# MAIN_CTRL_MMR_MAIN_CTRL_MMR_CFG0_00100000h register map
Vendor: Texas Instruments
Registers are 32-bit, read-write, reset 0x0 unless marked. A register's access mark holds for its fields unless they carry their own. Offsets are as the file gives them; [hi:lo] are bit positions; {n}, {i} and the like mark numbered series.

## main_ctrl_mmr_CFG0 (part 3 of 3)
0x4774 MAIN_CTRL_MMRCFG0_R5SS1_CORE1_RL2_CTRL — Controls operation of the RL2 Cache Controller for Main R5 Cluster1 Core1. Note this register has no effect if Main R5 Cluster0 is operating in lockstep mode.
  [9:8] R5SS1_CORE1_RL2_CTRL_RTXIP_SEL — Selects R5SS1 Core 1 OSPI0 XIP realtime access modeWhen realtime accesses are enabled, read transactions take priority over write transactions. This prevents XIP delays when Flash RWW updates are active.Field values (others are reserved):2'b00 - No realtime accesses2'b01 - Realtime access on RL2 Flash read pending2'b10 - All read accesses are realtime Reset Source: mod_g_rst_n
0x5110 MAIN_CTRL_MMRCFG0_CLAIMREG_P1_R4_READONLY ro
  [31:0] CLAIMREG_P1_R4_READONLY — Claim bits for Partition 1 Reset Source: mod_g_rst_n
0x5120 MAIN_CTRL_MMRCFG0_CLAIMREG_P1_R8_READONLY ro
  [31:0] CLAIMREG_P1_R8_READONLY — Claim bits for Partition 1 Reset Source: mod_g_rst_n
0x5124 MAIN_CTRL_MMRCFG0_CLAIMREG_P1_R9_READONLY ro
  [31:0] CLAIMREG_P1_R9_READONLY — Claim bits for Partition 1 Reset Source: mod_g_rst_n
0x6044 MAIN_CTRL_MMRCFG0_ENET1_CTRL_PROXY reset 0x2 — Controls Ethernet Port1 operation
  [2:0] ENET1_CTRL_PORT_MODE_SEL_PROXY — Selects Ethernet switch Port1 interface Field values (others are reserved):3'b000 - GMII/MII (not supported)3'b001 - RMII3'b010 - RGMII3'b011 - SGMII3'b100 - QSGMII (not supported)3'b101 - XFI (not supported)3'b110 - QSGMII_SUB (not supported)3'b111 - Reserved Reset Source: sys_por_rst_n
0x6048 MAIN_CTRL_MMRCFG0_ENET2_CTRL_PROXY reset 0x2 — Controls Ethernet Port2 operation
  [2:0] ENET2_CTRL_PORT_MODE_SEL_PROXY — Selects Ethernet switch Port2 interface Field values (others are reserved):3'b000 - GMII/MII (not supported)3'b001 - RMII3'b010 - RGMII3'b011 - SGMII3'b100 - QSGMII (not supported)3'b101 - XFI (not supported)3'b110 - QSGMII_SUB (not supported)3'b111 - Reserved Reset Source: sys_por_rst_n
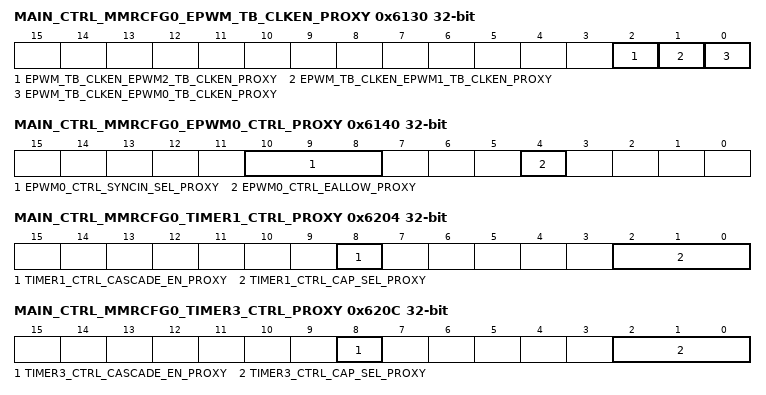
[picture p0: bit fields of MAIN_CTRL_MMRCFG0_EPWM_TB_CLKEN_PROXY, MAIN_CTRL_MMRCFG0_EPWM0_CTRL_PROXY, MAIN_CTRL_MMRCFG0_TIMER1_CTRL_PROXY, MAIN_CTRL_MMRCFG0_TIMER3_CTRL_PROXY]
0x6130 MAIN_CTRL_MMRCFG0_EPWM_TB_CLKEN_PROXY — Controls Timebase Counter of EPWM Modules
  [2] EPWM_TB_CLKEN_EPWM2_TB_CLKEN_PROXY — Enabled Timebase Clock of EPWM2 When SetField values (others are reserved):1'b0 - Disable1'b1 - Enable Reset Source: mod_g_rst_n
  [1] EPWM_TB_CLKEN_EPWM1_TB_CLKEN_PROXY — EnablesTimebase Clock of EPWM1 When SetField values (others are reserved):1'b0 - Disable1'b1 - Enable Reset Source: mod_g_rst_n
  [0] EPWM_TB_CLKEN_EPWM0_TB_CLKEN_PROXY — EnablesTimebase Clock of EPWM0 When SetField values (others are reserved):1'b0 - Disable1'b1 - Enable Reset Source: mod_g_rst_n
0x6140 MAIN_CTRL_MMRCFG0_EPWM0_CTRL_PROXY — Controls EPWM0 Operation
  [10:8] EPWM0_CTRL_SYNCIN_SEL_PROXY — Selects the source of the EPWM0 synchronization inputField values (others are reserved):3'b000 - EPWM0_SYNCIN (Pin)undefined - undefined3'b010 - TimeSync Intr Router outl.203'b011 - CPSW CPTS Compare Event Reset Source: mod_g_rst_n
  [4] EPWM0_CTRL_EALLOW_PROXY — Enable write access to EPWM tripzone registersField values (others are reserved):1'b0 - Disable1'b1 - Enable Reset Source: mod_g_rst_n
0x6144 MAIN_CTRL_MMRCFG0_EPWM1_CTRL_PROXY — Controls EPWM1 Operation
  [4] EPWM1_CTRL_EALLOW_PROXY — Enable write access to EPWM tripzone registersField values (others are reserved):1'b0 - Disable1'b1 - Enable Reset Source: mod_g_rst_n
0x6148 MAIN_CTRL_MMRCFG0_EPWM2_CTRL_PROXY — Controls EPWM2 Operation
  [4] EPWM2_CTRL_EALLOW_PROXY — Enable write access to EPWM tripzone registersField values (others are reserved):1'b0 - Disable1'b1 - Enable Reset Source: mod_g_rst_n
0x6200 MAIN_CTRL_MMRCFG0_TIMER0_CTRL_PROXY — Controls TIMER0 operation
  [2:0] TIMER0_CTRL_CAP_SEL_PROXY — Selects the TIMERIO input pin for capture input signal. This control is only used when TIMER0 is configured for capture operation.Field values (others are reserved):3'b000 - Use TIMERIO0 pin3'b001 - Use TIMERIO1 pin3'b010 - Use TIMERIO2 pin3'b011 - Use TIMERIO3 pin3'b100 - Use TIMERIO4 pin3'b101 - Use TIMERIO5 pin3'b110 - Use TIMERIO6 pin3'b111 - Use TIMERIO7 pin Reset Source: sys_por_rst_n
0x6204 MAIN_CTRL_MMRCFG0_TIMER1_CTRL_PROXY — Controls TIMER1 operation
  [8] TIMER1_CTRL_CASCADE_EN_PROXY — Enables cascading of TIMER1 to TIMER0Field values (others are reserved):1'b0 - Cascading disabled1'b1 - Cascading enabled Reset Source: sys_por_rst_n
  [2:0] TIMER1_CTRL_CAP_SEL_PROXY — Selects the TIMERIO input pin for capture input signal. This control is only used when TIMER1 is configured for capture operation.Field values (others are reserved):3'b000 - Use TIMERIO0 pin3'b001 - Use TIMERIO1 pin3'b010 - Use TIMERIO2 pin3'b011 - Use TIMERIO3 pin3'b100 - Use TIMERIO4 pin3'b101 - Use TIMERIO5 pin3'b110 - Use TIMERIO6 pin3'b111 - Use TIMERIO7 pin Reset Source: sys_por_rst_n
0x6208 MAIN_CTRL_MMRCFG0_TIMER2_CTRL_PROXY — Controls TIMER2 operation
  [2:0] TIMER2_CTRL_CAP_SEL_PROXY — Selects the TIMERIO input pin for capture input signal. This control is only used when TIMER2 is configured for capture operation.Field values (others are reserved):3'b000 - Use TIMERIO0 pin3'b001 - Use TIMERIO1 pin3'b010 - Use TIMERIO2 pin3'b011 - Use TIMERIO3 pin3'b100 - Use TIMERIO4 pin3'b101 - Use TIMERIO5 pin3'b110 - Use TIMERIO6 pin3'b111 - Use TIMERIO7 pin Reset Source: sys_por_rst_n
0x620C MAIN_CTRL_MMRCFG0_TIMER3_CTRL_PROXY — Controls TIMER3 operation
  [8] TIMER3_CTRL_CASCADE_EN_PROXY — Enables cascading of TIMER3 to TIMER2Field values (others are reserved):1'b0 - Cascading disabled1'b1 - Cascading enabled Reset Source: sys_por_rst_n
  [2:0] TIMER3_CTRL_CAP_SEL_PROXY — Selects the TIMERIO input pin for capture input signal. This control is only used when TIMER3 is configured for capture operation.Field values (others are reserved):3'b000 - Use TIMERIO0 pin3'b001 - Use TIMERIO1 pin3'b010 - Use TIMERIO2 pin3'b011 - Use TIMERIO3 pin3'b100 - Use TIMERIO4 pin3'b101 - Use TIMERIO5 pin3'b110 - Use TIMERIO6 pin3'b111 - Use TIMERIO7 pin Reset Source: sys_por_rst_n
0x6210 MAIN_CTRL_MMRCFG0_TIMER4_CTRL_PROXY — Controls TIMER4 operation
  [2:0] TIMER4_CTRL_CAP_SEL_PROXY — Selects the TIMERIO input pin for capture input signal. This control is only used when TIMER4 is configured for capture operation.Field values (others are reserved):3'b000 - Use TIMERIO0 pin3'b001 - Use TIMERIO1 pin3'b010 - Use TIMERIO2 pin3'b011 - Use TIMERIO3 pin3'b100 - Use TIMERIO4 pin3'b101 - Use TIMERIO5 pin3'b110 - Use TIMERIO6 pin3'b111 - Use TIMERIO7 pin Reset Source: sys_por_rst_n
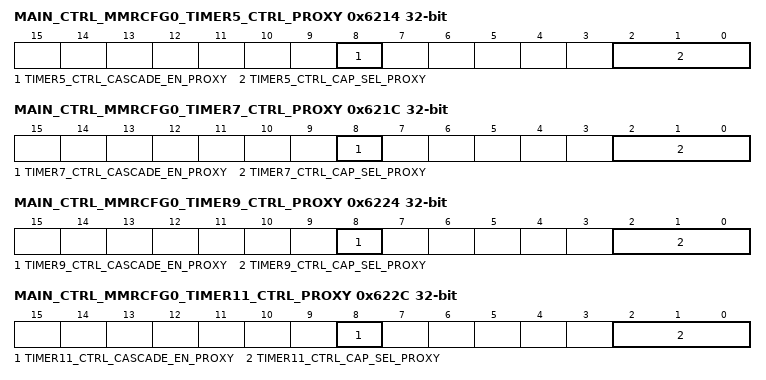
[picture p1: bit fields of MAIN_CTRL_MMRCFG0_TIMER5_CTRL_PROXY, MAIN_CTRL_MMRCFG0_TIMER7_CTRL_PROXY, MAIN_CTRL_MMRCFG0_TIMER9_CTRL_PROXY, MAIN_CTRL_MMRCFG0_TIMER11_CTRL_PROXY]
0x6214 MAIN_CTRL_MMRCFG0_TIMER5_CTRL_PROXY — Controls TIMER5 operation
  [8] TIMER5_CTRL_CASCADE_EN_PROXY — Enables cascading of TIMER5 to TIMER4Field values (others are reserved):1'b0 - Cascading disabled1'b1 - Cascading enabled Reset Source: sys_por_rst_n
  [2:0] TIMER5_CTRL_CAP_SEL_PROXY — Selects the TIMERIO input pin for capture input signal. This control is only used when TIMER5 is configured for capture operation.Field values (others are reserved):3'b000 - Use TIMERIO0 pin3'b001 - Use TIMERIO1 pin3'b010 - Use TIMERIO2 pin3'b011 - Use TIMERIO3 pin3'b100 - Use TIMERIO4 pin3'b101 - Use TIMERIO5 pin3'b110 - Use TIMERIO6 pin3'b111 - Use TIMERIO7 pin Reset Source: sys_por_rst_n
0x6218 MAIN_CTRL_MMRCFG0_TIMER6_CTRL_PROXY — Controls TIMER6 operation
  [2:0] TIMER6_CTRL_CAP_SEL_PROXY — Selects the TIMERIO input pin for capture input signal. This control is only used when TIMER6 is configured for capture operation.Field values (others are reserved):3'b000 - Use TIMERIO0 pin3'b001 - Use TIMERIO1 pin3'b010 - Use TIMERIO2 pin3'b011 - Use TIMERIO3 pin3'b100 - Use TIMERIO4 pin3'b101 - Use TIMERIO5 pin3'b110 - Use TIMERIO6 pin3'b111 - Use TIMERIO7 pin Reset Source: sys_por_rst_n
0x621C MAIN_CTRL_MMRCFG0_TIMER7_CTRL_PROXY — Controls TIMER7 operation
  [8] TIMER7_CTRL_CASCADE_EN_PROXY — Enables cascading of TIMER7 to TIMER6Field values (others are reserved):1'b0 - Cascading disabled1'b1 - Cascading enabled Reset Source: sys_por_rst_n
  [2:0] TIMER7_CTRL_CAP_SEL_PROXY — Selects the TIMERIO input pin for capture input signal. This control is only used when TIMER7 is configured for capture operation.Field values (others are reserved):3'b000 - Use TIMERIO0 pin3'b001 - Use TIMERIO1 pin3'b010 - Use TIMERIO2 pin3'b011 - Use TIMERIO3 pin3'b100 - Use TIMERIO4 pin3'b101 - Use TIMERIO5 pin3'b110 - Use TIMERIO6 pin3'b111 - Use TIMERIO7 pin Reset Source: sys_por_rst_n
0x6220 MAIN_CTRL_MMRCFG0_TIMER8_CTRL_PROXY — Controls TIMER8 operation
  [2:0] TIMER8_CTRL_CAP_SEL_PROXY — Selects the TIMERIO input pin for capture input signal. This control is only used when TIMER8 is configured for capture operation.Field values (others are reserved):3'b000 - Use TIMERIO0 pin3'b001 - Use TIMERIO1 pin3'b010 - Use TIMERIO2 pin3'b011 - Use TIMERIO3 pin3'b100 - Use TIMERIO4 pin3'b101 - Use TIMERIO5 pin3'b110 - Use TIMERIO6 pin3'b111 - Use TIMERIO7 pin Reset Source: sys_por_rst_n
0x6224 MAIN_CTRL_MMRCFG0_TIMER9_CTRL_PROXY — Controls TIMER9 operation
  [8] TIMER9_CTRL_CASCADE_EN_PROXY — Enables cascading of TIMER9 to TIMER8Field values (others are reserved):1'b0 - Cascading disabled1'b1 - Cascading enabled Reset Source: sys_por_rst_n
  [2:0] TIMER9_CTRL_CAP_SEL_PROXY — Selects the TIMERIO input pin for capture input signal. This control is only used when TIMER9 is configured for capture operation.Field values (others are reserved):3'b000 - Use TIMERIO0 pin3'b001 - Use TIMERIO1 pin3'b010 - Use TIMERIO2 pin3'b011 - Use TIMERIO3 pin3'b100 - Use TIMERIO4 pin3'b101 - Use TIMERIO5 pin3'b110 - Use TIMERIO6 pin3'b111 - Use TIMERIO7 pin Reset Source: sys_por_rst_n
0x6228 MAIN_CTRL_MMRCFG0_TIMER10_CTRL_PROXY — Controls TIMER10 operation
  [2:0] TIMER10_CTRL_CAP_SEL_PROXY — Selects the TIMERIO input pin for capture input signal. This control is only used when TIMER10 is configured for capture operation.Field values (others are reserved):3'b000 - Use TIMERIO0 pin3'b001 - Use TIMERIO1 pin3'b010 - Use TIMERIO2 pin3'b011 - Use TIMERIO3 pin3'b100 - Use TIMERIO4 pin3'b101 - Use TIMERIO5 pin3'b110 - Use TIMERIO6 pin3'b111 - Use TIMERIO7 pin Reset Source: sys_por_rst_n
0x622C MAIN_CTRL_MMRCFG0_TIMER11_CTRL_PROXY — Controls TIMER11 operation
  [8] TIMER11_CTRL_CASCADE_EN_PROXY — Enables cascading of TIMER11 to TIMER10Field values (others are reserved):1'b0 - Cascading disabled1'b1 - Cascading enabled Reset Source: sys_por_rst_n
  [2:0] TIMER11_CTRL_CAP_SEL_PROXY — Selects the TIMERIO input pin for capture input signal. This control is only used when TIMER11 is configured for capture operation.Field values (others are reserved):3'b000 - Use TIMERIO0 pin3'b001 - Use TIMERIO1 pin3'b010 - Use TIMERIO2 pin3'b011 - Use TIMERIO3 pin3'b100 - Use TIMERIO4 pin3'b101 - Use TIMERIO5 pin3'b110 - Use TIMERIO6 pin3'b111 - Use TIMERIO7 pin Reset Source: sys_por_rst_n
0x6230 MAIN_CTRL_MMRCFG0_TIMER12_CTRL_PROXY — Controls TIMER12 operation
  [2:0] TIMER12_CTRL_CAP_SEL_PROXY — Selects the TIMERIO input pin for capture input signal. This control is only used when TIMER12 is configured for capture operation.Field values (others are reserved):3'b000 - Use TIMERIO0 pin3'b001 - Use TIMERIO1 pin3'b010 - Use TIMERIO2 pin3'b011 - Use TIMERIO3 pin3'b100 - Use TIMERIO4 pin3'b101 - Use TIMERIO5 pin3'b110 - Use TIMERIO6 pin3'b111 - Use TIMERIO7 pin Reset Source: sys_por_rst_n
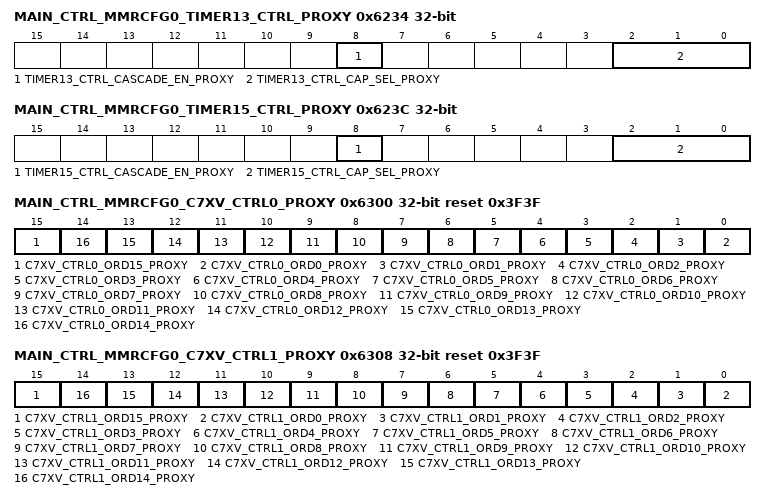
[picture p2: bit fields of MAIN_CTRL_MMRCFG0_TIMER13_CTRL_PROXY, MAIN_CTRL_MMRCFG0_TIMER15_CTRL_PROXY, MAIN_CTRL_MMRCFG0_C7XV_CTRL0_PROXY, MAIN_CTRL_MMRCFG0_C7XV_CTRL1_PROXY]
0x6234 MAIN_CTRL_MMRCFG0_TIMER13_CTRL_PROXY — Controls TIMER13 operation
  [8] TIMER13_CTRL_CASCADE_EN_PROXY — Enables cascading of TIMER13 to TIMER12Field values (others are reserved):1'b0 - Cascading disabled1'b1 - Cascading enabled Reset Source: sys_por_rst_n
  [2:0] TIMER13_CTRL_CAP_SEL_PROXY — Selects the TIMERIO input pin for capture input signal. This control is only used when TIMER13 is configured for capture operation.Field values (others are reserved):3'b000 - Use TIMERIO0 pin3'b001 - Use TIMERIO1 pin3'b010 - Use TIMERIO2 pin3'b011 - Use TIMERIO3 pin3'b100 - Use TIMERIO4 pin3'b101 - Use TIMERIO5 pin3'b110 - Use TIMERIO6 pin3'b111 - Use TIMERIO7 pin Reset Source: sys_por_rst_n
0x6238 MAIN_CTRL_MMRCFG0_TIMER14_CTRL_PROXY — Controls TIMER14 operation
  [2:0] TIMER14_CTRL_CAP_SEL_PROXY — Selects the TIMERIO input pin for capture input signal. This control is only used when TIMER14 is configured for capture operation.Field values (others are reserved):3'b000 - Use TIMERIO0 pin3'b001 - Use TIMERIO1 pin3'b010 - Use TIMERIO2 pin3'b011 - Use TIMERIO3 pin3'b100 - Use TIMERIO4 pin3'b101 - Use TIMERIO5 pin3'b110 - Use TIMERIO6 pin3'b111 - Use TIMERIO7 pin Reset Source: sys_por_rst_n
0x623C MAIN_CTRL_MMRCFG0_TIMER15_CTRL_PROXY — Controls TIMER15 operation
  [8] TIMER15_CTRL_CASCADE_EN_PROXY — Enables cascading of TIMER15 to TIMER14Field values (others are reserved):1'b0 - Cascading disabled1'b1 - Cascading enabled Reset Source: sys_por_rst_n
  [2:0] TIMER15_CTRL_CAP_SEL_PROXY — Selects the TIMERIO input pin for capture input signal. This control is only used when TIMER15 is configured for capture operation.Field values (others are reserved):3'b000 - Use TIMERIO0 pin3'b001 - Use TIMERIO1 pin3'b010 - Use TIMERIO2 pin3'b011 - Use TIMERIO3 pin3'b100 - Use TIMERIO4 pin3'b101 - Use TIMERIO5 pin3'b110 - Use TIMERIO6 pin3'b111 - Use TIMERIO7 pin Reset Source: sys_por_rst_n
{0x6280+4i} MAIN_CTRL_MMRCFG0_TIMERIO{i}_CTRL_PROXY (i=0..7) — Controls Timer IO muxing
  [3:0] TIMERIO{i}_CTRL_OUT_SEL_PROXY — Selects the source of the TIMERIO{i} outputField values (others are reserved):4'b0000 - TIMERIO{i} is driven by TIMER0 output4'b0001 - TIMERIO{i} is driven by TIMER1 output4'b0010 - TIMERIO{i} is driven by TIMER2 output4'b0011 - TIMERIO{i} is driven by TIMER3 output4'b0100 - TIMERIO{i} is driven by TIMER4 output4'b0101 - TIMERIO{i} is driven by TIMER5 output4'b0110 - TIMERIO{i} is driven by TIMER6 output4'b0111 - TIMERIO{i} is driven by TIMER7 output4'b1000 - TIMERIO{i} is driven by TIMER8 output4'b1001 - TIMERIO{i} is driven by TIMER9 output4'b1010 - TIMERIO{i} is driven by TIMER10 output4'b1011 - TIMERIO{i} is driven by TIMER11 output4'b1100 - TIMERIO{i} is driven by TIMER12 output4'b1101 - TIMERIO{i} is driven by TIMER13 output4'b1110 - TIMERIO{i} is driven by TIMER14 output4'b1111 - TIMERIO{i} is driven by TIMER15 output Reset Source: sys_por_rst_n
0x6300 MAIN_CTRL_MMRCFG0_C7XV_CTRL0_PROXY reset 0x3F3F — Controls Relaxed Ordering by OrderID for the C7xv0 L2 Memory from external accesses. Ordering of accesses to the same 4KB L2 Block is relaxed either between Reads (more strict) or Between both Reads and Writes (more relaxed)
  [15] C7XV_CTRL0_ORD15_PROXY — Ordering Rule for Order ID 15 Field values (others are reserved):1'b0 - RELAXED_READ1'b1 - RELAXED_R_TO_W Reset Source: mod_por_rst_n
  [n] C7XV_CTRL0_ORD{n}_PROXY (n=0..14) — Ordering Rule for Order ID {n}Field values (others are reserved):1'b0 - RELAXED_READ1'b1 - RELAXED_R_TO_W Reset Source: mod_por_rst_n
0x6308 MAIN_CTRL_MMRCFG0_C7XV_CTRL1_PROXY reset 0x3F3F — Controls Relaxed Ordering by OrderID for the C7xv1 L2 Memory from external accesses. Ordering of accesses to the same 4KB L2 Block is relaxed either between Reads (more strict) or Between both Reads and Writes (more relaxed)
  [15] C7XV_CTRL1_ORD15_PROXY — Ordering Rule for Order ID 15 Field values (others are reserved):1'b0 - RELAXED_READ1'b1 - RELAXED_R_TO_W Reset Source: mod_por_rst_n
  [n] C7XV_CTRL1_ORD{n}_PROXY (n=0..14) — Ordering Rule for Order ID {n}Field values (others are reserved):1'b0 - RELAXED_READ1'b1 - RELAXED_R_TO_W Reset Source: mod_por_rst_n
0x64C0 MAIN_CTRL_MMRCFG0_EMMC0_STAT_PROXY ro — For determining state of MMCSD 1.8V Signalling
  [0] EMMC0_STAT_SIG1P8_EN_PROXY — Status of 1.8V Signal Activate from EMMC0 ModuleField values (others are reserved):1'b0 - DISABLE_1P8V_SIGNALLING1'b1 - ENABLE_1P8V_SIGNALLING Reset Source: mod_g_rst_n
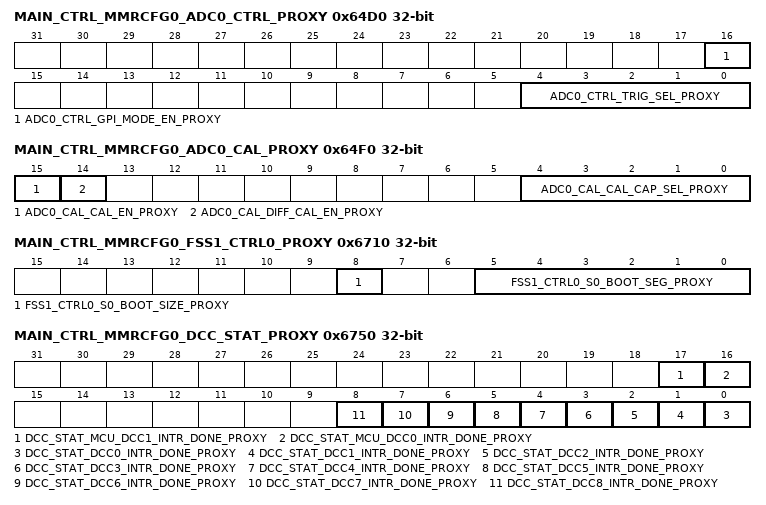
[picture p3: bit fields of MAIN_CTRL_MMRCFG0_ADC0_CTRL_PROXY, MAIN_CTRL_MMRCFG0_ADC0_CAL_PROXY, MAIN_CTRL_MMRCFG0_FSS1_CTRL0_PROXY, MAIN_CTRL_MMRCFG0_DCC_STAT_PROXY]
0x64D0 MAIN_CTRL_MMRCFG0_ADC0_CTRL_PROXY — Controls operation of ADC0
  [16] ADC0_CTRL_GPI_MODE_EN_PROXY — Enables ADC0 data pins to be used as general purpose inputs when set. This signal is tied to the en_dig_test input of MCU_ADC0 Reset Source: mod_g_rst_n
  [4:0] ADC0_CTRL_TRIG_SEL_PROXY — Selects the source of the ADC hardware event triggerField values (others are reserved):5'b00000 - ADC_EXT_TRIGGER0 (Pin)5'b00001 - 0 - Reserved5'b00010 - EPWM SOCA_OUT5'b00011 - EPWM SOCB_OUT5'b00100 - 0 - Reserved5'b00101 - 0 - Reserved5'b00110 - 0 - Reserved5'b00111 - 0 - Reserved5'b01000 - 0 - Reserved5'b01001 - 0 - Reserved5'b01010 - 0 - Reserved5'b01011 - 0 - Reserved5'b01100 - 0 - Reserved5'b01101 - 0 - Reserved5'b01110 - WKUP_TIMER0 PWM5'b01111 - WKUP_TIMER1 PWM5'b10000 - TIMER0 PWM 5'b10001 - TIMER1 PWM 5'b10010 - TIMER2 PWM 5'b10011 - TIMER3 PWM 5'b10100 - TIMER4 PWM 5'b10101 - TIMER5 PWM 5'b10110 - TIMER6 PWM 5'b10111 - TIMER7 PWM 5'b11000 - TIMER8 PWM 5'b11001 - TIMER9 PWM 5'b11010 - TIMER10 PWM 5'b11011 - TIMER11 PWM 5'b11100 - TIMER12 PWM5'b11101 - TIMER13_PWM5'b11110 - TIMER14_pWM5'b11111 - Timer15_PWM Reset Source: mod_g_rst_n
0x64F0 MAIN_CTRL_MMRCFG0_ADC0_CAL_PROXY — Controls ADC0 calibration sequence (not used)
  [15] ADC0_CAL_CAL_EN_PROXY — Enable single-ended calibrationSet to 1 to begin single-ended calibration Reset Source: mod_g_rst_n
  [14] ADC0_CAL_DIFF_CAL_EN_PROXY — Enable differential calibrationSet to 1 to begin differential calibration Reset Source: mod_g_rst_n
  [4:0] ADC0_CAL_CAL_CAP_SEL_PROXY — Select capacitor for calibrationBits correspond to C5:C1 Reset Source: mod_g_rst_n
0x6700 MAIN_CTRL_MMRCFG0_FSS0_CTRL0_PROXY — Controls Flash boot region size for Flash Subsystem0
  [19:0] FSS0_CTRL0_S0_BOOT_SEG_PROXY — Selects the flash boot segment sizeField values (others are reserved):20'h00001 - 4 kB20'h00002 - 8 kB20'h00004 - 16 kB20'h00008 - 32 kB20'h00010 - 64 kB20'h00020 - 128 kB20'h00040 - 256 kB20'h00080 - 512 kB20'h00100 - 1 MB20'h00200 - 2 MB20'h00400 - 4 MB20'h00800 - 8 MB20'h01000 - 16 MB20'h02000 - 32 MB20'h04000 - 64 MB20'h08000 - 128 MB20'h10000 - 256 MB20'h20000 - 512 MB20'h40000 - 1 GB20'h80000 - 2 GB Reset Source: mod_g_rst_n
0x6704 MAIN_CTRL_MMRCFG0_FSS0_CTRL1_PROXY — Controls Flash boot region placement for Flash Subsystem0
  [19:0] FSS0_CTRL1_S0_BOOT_MASK_PROXY — Determines which (upper 20) address bits to replace with boot_seg signals when accessing the Boot Region (Region 1) Reset Source: mod_g_rst_n
0x6710 MAIN_CTRL_MMRCFG0_FSS1_CTRL0_PROXY — Controls Flash boot region size and placement for Flash Subsystem1
  [8] FSS1_CTRL0_S0_BOOT_SIZE_PROXY — Selects the size of the boot block to be used for the S0 (OSPI1) flash interface Reset Source: mod_g_rst_n
  [5:0] FSS1_CTRL0_S0_BOOT_SEG_PROXY — Selects the boot block to be used for the S0 (OSPI1) flash interface. If the s0_boot_size is 128 MB then only bits [4:0] of this field are used. Care must be taken to account for the address translation as to not fall off or wrap the address of the flash. (e.g. if both ECC and authentication are enabled for 64 MB boot, the highest valid block number is is 49, as sector 50 is only .2M Bytes in size.) Reset Source: mod_g_rst_n
0x6750 MAIN_CTRL_MMRCFG0_DCC_STAT_PROXY ro — Interrupt Status of Individual DCC Modules
  [17] DCC_STAT_MCU_DCC1_INTR_DONE_PROXY — MCU_DCC1 Done Interrupt StatusField values (others are reserved):1'b0 - CLR1'b1 - PEND Reset Source: mod_g_rst_n
  [16] DCC_STAT_MCU_DCC0_INTR_DONE_PROXY — MCU_DCC0 Done Interrupt StatusField values (others are reserved):1'b0 - CLR1'b1 - PEND Reset Source: mod_g_rst_n
  [n] DCC_STAT_DCC{n}_INTR_DONE_PROXY (n=0..8) — DCC{n} Done Interrupt StatusField values (others are reserved):1'b0 - CLR1'b1 - PEND Reset Source: mod_g_rst_n
0x6760 MAIN_CTRL_MMRCFG0_R5SS0_CORE0_RL2_CTRL_PROXY — Controls operation of the RL2 Cache Controller for Main R5 Cluster0 Core0
  [9:8] R5SS0_CORE0_RL2_CTRL_RTXIP_SEL_PROXY — Selects R5SS0 Core 0 OSPI0 XIP realtime access modeWhen realtime accesses are enabled, read transactions take priority over write transactions. This prevents XIP delays when Flash RWW updates are active.Field values (others are reserved):2'b00 - No realtime accesses2'b01 - Realtime access on RL2 Flash read pending2'b10 - All read accesses are realtime Reset Source: mod_g_rst_n
0x6764 MAIN_CTRL_MMRCFG0_R5SS0_CORE1_RL2_CTRL_PROXY — Controls operation of the RL2 Cache Controller for Main R5 Cluster0 Core1. Note this register has no effect if Main R5 Cluster0 is operating in lockstep mode.
  [9:8] R5SS0_CORE1_RL2_CTRL_RTXIP_SEL_PROXY — Selects R5SS0 Core 1 OSPI0 XIP realtime access modeWhen realtime accesses are enabled, read transactions take priority over write transactions. This prevents XIP delays when Flash RWW updates are active.Field values (others are reserved):2'b00 - No realtime accesses2'b01 - Realtime access on RL2 Flash read pending2'b10 - All read accesses are realtime Reset Source: mod_g_rst_n
0x6770 MAIN_CTRL_MMRCFG0_R5SS1_CORE0_RL2_CTRL_PROXY — Controls operation of the RL2 Cache Controller for Main R5 Cluster1 Core0
  [9:8] R5SS1_CORE0_RL2_CTRL_RTXIP_SEL_PROXY — Selects R5SS1 Core 0 OSPI0 XIP realtime access modeWhen realtime accesses are enabled, read transactions take priority over write transactions. This prevents XIP delays when Flash RWW updates are active.Field values (others are reserved):2'b00 - No realtime accesses2'b01 - Realtime access on RL2 Flash read pending2'b10 - All read accesses are realtime Reset Source: mod_g_rst_n
0x6774 MAIN_CTRL_MMRCFG0_R5SS1_CORE1_RL2_CTRL_PROXY — Controls operation of the RL2 Cache Controller for Main R5 Cluster1 Core1. Note this register has no effect if Main R5 Cluster0 is operating in lockstep mode.
  [9:8] R5SS1_CORE1_RL2_CTRL_RTXIP_SEL_PROXY — Selects R5SS1 Core 1 OSPI0 XIP realtime access modeWhen realtime accesses are enabled, read transactions take priority over write transactions. This prevents XIP delays when Flash RWW updates are active.Field values (others are reserved):2'b00 - No realtime accesses2'b01 - Realtime access on RL2 Flash read pending2'b10 - All read accesses are realtime Reset Source: mod_g_rst_n
{0x7100+4i} MAIN_CTRL_MMRCFG0_CLAIMREG_P1_R{i} (i=0..14)
  [31:0] CLAIMREG_P1_R{i} — Claim bits for Partition 1 Reset Source: mod_g_rst_n
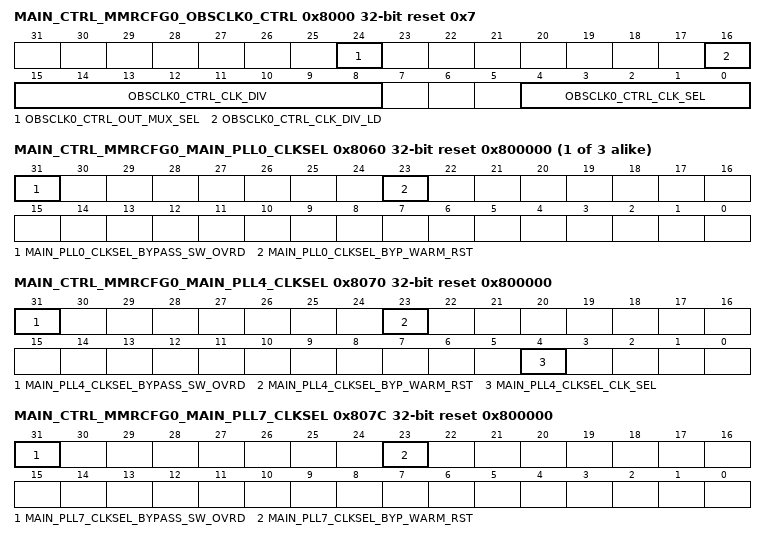
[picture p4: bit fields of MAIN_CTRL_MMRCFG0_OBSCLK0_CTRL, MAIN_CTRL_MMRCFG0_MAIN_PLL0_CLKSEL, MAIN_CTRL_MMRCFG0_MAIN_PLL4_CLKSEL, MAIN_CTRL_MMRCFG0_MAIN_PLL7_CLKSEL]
0x8000 MAIN_CTRL_MMRCFG0_OBSCLK0_CTRL reset 0x7 — This register controls which internal clock is made observable on the OBSCLK0/1 output pins
  [24] OBSCLK0_CTRL_OUT_MUX_SEL — OBSCLK pin output mux selection. PLL4_REFCLK is the direct output from either HFOSC0 or HFOSC1.Field values (others are reserved):1'b0 - Selects the output of the CLK_DIV_OUT clock mux1'b1 - Select PLL4_REFCLK (clk_sel value must be 5'b11111) Reset Source: mod_por_rst_n
  [16] OBSCLK0_CTRL_CLK_DIV_LD — Load divisor value from clk_div field, when the bit is toggled from 0 to 1. Field values (others are reserved):1'b0 - READY1'b1 - LOAD Reset Source: mod_por_rst_n
  [15:8] OBSCLK0_CTRL_CLK_DIV — OBSCLK0 output divider. Sets divider to divide by clkdiv + 1. Divide by 1 to 256 are supported. After Writing to this field, the clk_div_ld field must be toggled. Reset Source: mod_por_rst_n
  [4:0] OBSCLK0_CTRL_CLK_SEL — OBSCLK0 clock source selection.Selects the source of the clock to be divided by the OBSCLK0 divider.Field values (others are reserved):5'b00000 - MAIN_PLL0_HSDIV0_CLKOUT5'b00001 - MAIN_PLL1_HSDIV0_CLKOUT5'b00010 - MAIN_PLL2_HSDIV0_CLKOUT5'b00011 - MAIN_PLL4_HSDIV0_CLKOUT5'b00100 - MAIN_PLL14_HSDIV0_CLKOUT5'b00101 - CLK_12M_RC5'b00110 - HFOSC0_CLKOUT_32K5'b00111 - PLLCTRL_OBSCLK5'b01000 - HFOSC0_CLKOUT5'b01001 - CLK_32K_RC5'b01010 - CPSW0_CPTS_GENF05'b01011 - CPSW0_CPTS_GENF15'b01100 - MCU_PLL0_HSDIV0_CLKOUT5'b01101 - MAIN_PLL15_HSDIV0_CLKOUTundefined - undefinedundefined - undefinedundefined - undefined5'b10000 - MAIN_SYSCLK05'b10001 - DEVICE_CLKOUT_32Kundefined - undefined5'b10011 - C7XV_CLK_DIV4undefined - undefinedundefined - undefined5'b11111 - OFF (Must Select this option when out_mux_sel is set to PLL4_REFCLK) Reset Source: mod_por_rst_n
0x8010 MAIN_CTRL_MMRCFG0_CLKOUT_CTRL — Enables and selects clock source of CPSW CLKOUT pin
  [0] CLKOUT_CTRL_CLK_SEL — Selects CLKOUT clock sourceField values (others are reserved):1'b0 - MAIN_PLL2_HSDIV1_CLKOUT / 51'b1 - MAIN_PLL2_HSDIV1_CLKOUT / 10 Reset Source: mod_g_rst_n
{0x8060+4i} MAIN_CTRL_MMRCFG0_MAIN_PLL{i}_CLKSEL reset 0x800000 (i=0..2) — Controls the clock source for MAIN voltage domain PLL{i}
  [31] MAIN_PLL{i}_CLKSEL_BYPASS_SW_OVRD — PLL Bypass warm reset software overrideWhen set, enables software control of exit from bypass mode on a main_reset_z for MAIN PLL{i}. This bit must not be set until after the corresponding byp_warm_rst bit has been cleared or the PLL will immediately enter bypass mode.Field values (others are reserved):1'b0 - Disable1'b1 - Enable Reset Source: sys_por_rst_n
  [23] MAIN_PLL{i}_CLKSEL_BYP_WARM_RST — PLL bypass mode after warm reset.This bit is only valid when bypass_sw_ovrd is set to 1'b1 to enable bypass software override.This bit is set (1'b1) when a MAIN warm reset occurs and will keep MAIN PLL{i} in bypass mode after reset exit until cleared by software.Field values (others are reserved):1'b0 - EXIT_BYPASS1'b1 - MAINTAIN_BYPASS Reset Source: main_chip1_rst_n
0x8070 MAIN_CTRL_MMRCFG0_MAIN_PLL4_CLKSEL reset 0x800000 — Controls the clock source for MAIN voltage domain PLL4
  [31] MAIN_PLL4_CLKSEL_BYPASS_SW_OVRD — PLL Bypass warm reset software overrideWhen set, enables software control of exit from bypass mode on a main_reset_z for MAIN PLL4. This bit must not be set until after the corresponding byp_warm_rst bit has been cleared or the PLL will immediately enter bypass mode.Field values (others are reserved):1'b0 - Disable1'b1 - Enable Reset Source: sys_por_rst_n
  [23] MAIN_PLL4_CLKSEL_BYP_WARM_RST — PLL bypass mode after warm reset.This bit is only valid when bypass_sw_ovrd is set to 1'b1 to enable bypass software override.This bit is set (1'b1) when a MAIN warm reset occurs and will keep MAIN PLL4 in bypass mode after reset exit until cleared by software.Field values (others are reserved):1'b0 - EXIT_BYPASS1'b1 - MAINTAIN_BYPASS Reset Source: main_chip1_rst_n
  [4] MAIN_PLL4_CLKSEL_CLK_SEL — Selects the clock source for MAIN PLL4 1'b0 - Use HFOSC0_CLKOUT 1'b1 - Use HFOSC1_CLKOUT Reset Source: mod_g_rst_n
0x807C MAIN_CTRL_MMRCFG0_MAIN_PLL7_CLKSEL reset 0x800000 — Controls the clock source for MAIN voltage domain PLL7
  [31] MAIN_PLL7_CLKSEL_BYPASS_SW_OVRD — PLL Bypass warm reset software overrideWhen set, enables software control of exit from bypass mode on a main_reset_z for MAIN PLL7. This bit must not be set until after the corresponding byp_warm_rst bit has been cleared or the PLL will immediately enter bypass mode.Field values (others are reserved):1'b0 - Disable1'b1 - Enable Reset Source: sys_por_rst_n
  [23] MAIN_PLL7_CLKSEL_BYP_WARM_RST — PLL bypass mode after warm reset.This bit is only valid when bypass_sw_ovrd is set to 1'b1 to enable bypass software override.This bit is set (1'b1) when a MAIN warm reset occurs and will keep MAIN PLL7 in bypass mode after reset exit until cleared by software.Field values (others are reserved):1'b0 - EXIT_BYPASS1'b1 - MAINTAIN_BYPASS Reset Source: main_chip1_rst_n
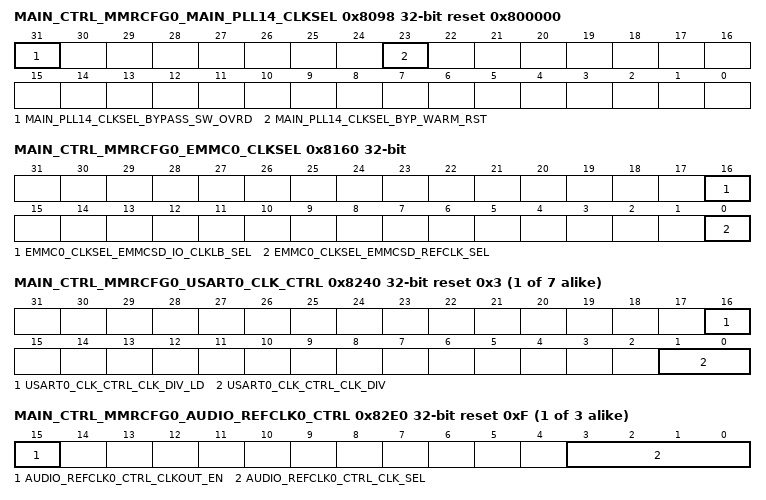
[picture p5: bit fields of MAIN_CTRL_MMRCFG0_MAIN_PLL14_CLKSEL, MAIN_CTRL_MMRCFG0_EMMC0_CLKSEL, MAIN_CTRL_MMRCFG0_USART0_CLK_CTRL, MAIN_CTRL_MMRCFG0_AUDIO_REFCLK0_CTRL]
0x8098 MAIN_CTRL_MMRCFG0_MAIN_PLL14_CLKSEL reset 0x800000 — Controls the clock source for MAIN voltage domain PLL14
  [31] MAIN_PLL14_CLKSEL_BYPASS_SW_OVRD — PLL Bypass warm reset software overrideWhen set, enables software control of exit from bypass mode on a main_reset_z for MAIN PLL14. This bit must not be set until after the corresponding byp_warm_rst bit has been cleared or the PLL will immediately enter bypass mode.Field values (others are reserved):1'b0 - Disable1'b1 - Enable Reset Source: sys_por_rst_n
  [23] MAIN_PLL14_CLKSEL_BYP_WARM_RST — PLL bypass mode after warm reset.This bit is only valid when bypass_sw_ovrd is set to 1'b1 to enable bypass software override.This bit is set (1'b1) when a MAIN warm reset occurs and will keep MAIN PLL14 in bypass mode after reset exit until cleared by software.Field values (others are reserved):1'b0 - EXIT_BYPASS1'b1 - MAINTAIN_BYPASS Reset Source: main_chip1_rst_n
0x8140 MAIN_CTRL_MMRCFG0_CPSW_CLKSEL reset 0x7 — Selects the CP Switch clock sources
  [2:0] CPSW_CLKSEL_CPTS_CLKSEL — Selects the clock source for the CPSW Ethernet switch Common Platform Time Stamp moduleField values (others are reserved):3'b000 - MAIN_PLL2_HSDIV5_CLKOUT3'b001 - MAIN_PLL0_HSDIV6_CLKOUT3'b010 - CP_GEMAC_CPTS0_RFT_CLK (Pin)3'b011 - Reserved3'b100 - MCU_EXT_REFCLK0 (Pin)3'b101 - EXT_REFCLK1 (Pin)3'b110 - SERDES0_IP1_LN0_TXMCLKundefined - undefined3'b111 - MAIN_SYSCLK0 Reset Source: mod_por_rst_n
0x8160 MAIN_CTRL_MMRCFG0_EMMC0_CLKSEL — Selects the functional clock source for 8-bit eMMC0
  [16] EMMC0_CLKSEL_EMMCSD_IO_CLKLB_SEL — Selects IO Pad Loopback for the MMC ModuleField values (others are reserved):1'b0 - Loopback from Unbonded Pad MMCSD0_CLKLB1'b1 - Loopback from IO Pin MMCSD0_CLK Reset Source: mod_g_rst_n
  [0] EMMC0_CLKSEL_EMMCSD_REFCLK_SEL — Selects the functional clock for the MMC ModuleField values (others are reserved):1'b0 - MAIN_PLL0_HSDIV5_CLKOUT1'b1 - MAIN_PLL2_HSDIV2_CLKOUT Reset Source: mod_g_rst_n
{0x81B0+4i} MAIN_CTRL_MMRCFG0_TIMER{i}_CLKSEL (i=0..15) — Timer{i} functional clock selection control
  [3:0] TIMER{i}_CLKSEL_CLK_SEL — Timer functional clock input select control.Field values (others are reserved):4'b0000 - HFOSC0_CLKOUT4'b0001 - DEVICE_CLKOUT_32K4'b0010 - MAIN_PLL0_HSDIV7_CLKOUT4'b0011 - CLK_12M_RC4'b0100 - MCU_EXT_REFCLK0 (Pin)4'b0101 - EXT_REFCLK1 (Pin)4'b0110 - Reserved4'b0111 - CP_GEMAC_CPTS0_RFT_CLK (Pin)4'b1000 - MAIN_PLL1_HSDIV3_CLKOUT4'b1001 - MAIN_PLL2_HSDIV6_CLKOUT4'b1010 - CPSW0_CPTS_GENF04'b1011 - CPSW0_CPTS_GENF14'b1100 - Reserved Reset Source: sys_por_rst_n
{0x8200+4i} MAIN_CTRL_MMRCFG0_SPI{i}_CLKSEL (i=0..4) — SPI{i} clock control
  [16] SPI{i}_CLKSEL_MSTR_LB_CLKSEL — Controller mode receive capture clock loopback selectionField values (others are reserved):1'b0 - INTERNAL_LOOPBACK1'b1 - EXTERNAL_LOOPBACK Reset Source: mod_g_rst_n
{0x8240+4i} MAIN_CTRL_MMRCFG0_USART{i}_CLK_CTRL reset 0x3 (i=0..6) — Selects the clock divider of the USART{i} functional clock
  [16] USART{i}_CLK_CTRL_CLK_DIV_LD — Load the output divider valueWriting 1 to this bit will generate a load pulse to load the USART{i} clock programmable divider value. This bit can be cleared but must not be set in the same write cycle in which the clk_div value is changed. Field values (others are reserved):1'b0 - READY1'b1 - LOAD Reset Source: mod_g_rst_n
  [1:0] USART{i}_CLK_CTRL_CLK_DIV — Selects the clock divider value. Supports divide values of 1 to 4 Default is /4. To load the new divider value the clk_div_ld bit must be cleared and then set to 1.Field values (others are reserved):2'b00 - Divide by 12'b01 - Divide by 22'b10 - Divide by 32'b11 - Divide by 4 Reset Source: mod_g_rst_n
{0x8280+4i} MAIN_CTRL_MMRCFG0_USART{i}_CLKSEL (i=0..6) — Selects the clock source for USART{i} functional clock
  [0] USART{i}_CLKSEL_CLK_SEL — Selects the clock source for UART{i}:Field values (others are reserved):1'b0 - MAIN_PLL1_HSDIV0_CLKOUT Divider Output (See USART{i}_CLK_CTRL)1'b1 - MAIN_PLL1_HSDIV1_CLKOUT Reset Source: mod_g_rst_n
0x82B0 MAIN_CTRL_MMRCFG0_ATL_CLKSEL — Selects the source of ATL PCLK which drives ATL Measurement and Adjustment Logic
  [2:0] ATL_CLKSEL_PCLK_SEL — Selects the PCLK clock sourceField values (others are reserved):3'b000 - MAIN_PLL2_HSDIV8_CLKOUT3'b001 - MAIN_PLL1_HSDIV6_CLKOUT3'b010 - MAIN_PLL2_HSDIV0_CLKOUT3'b011 - MAIN_PLL4_HSDIV1_CLKOUT3'b100 - MAIN_PLL0_HSDIV7_CLKOUT3'b101 - MCU_EXT_REFCLK0 (Pin)3'b110 - EXT_REFCLK1 (Pin) Reset Source: mod_g_rst_n
{0x82C0+4i} MAIN_CTRL_MMRCFG0_ATL_BWS{i}_SEL (i=0..3) — Selects the word clock for the ATL channel{i} Baseband Stream
  [3:0] ATL_BWS{i}_SEL_WD_SEL — BWS source signalField values (others are reserved):4'b0000 - MCASP0_AFSR_IN4'b0001 - MCASP1_AFSR_IN4'b0010 - MCASP2_AFSR_IN4'b0011 - MCASP3_AFSR_IN4'b0100 - MCASP4_AFSR_IN4'b0101 - MCASP0_AFSX_IN4'b0110 - MCASP1_AFSX_IN4'b0111 - MCASP2_AFSX_IN4'b1000 - MCASP3_AFSX_IN4'b1001 - MCASP4_AFSX_IN4'b1010 - AUDIO_EXT_REFCLK0_IN4'b1011 - AUDIO_EXT_REFCLK1_IN4'b1100 - AUDIO_EXT_REFCLK2_IN Reset Source: mod_g_rst_n
{0x82D0+4i} MAIN_CTRL_MMRCFG0_ATL_AWS{i}_SEL (i=0..3) — Selects the word clock for the ATL channel{i} Audio Stream
  [3:0] ATL_AWS{i}_SEL_WD_SEL — AWS source signalField values (others are reserved):4'b0000 - MCASP0_AFSX_IN4'b0001 - MCASP1_AFSX_IN4'b0010 - MCASP2_AFSX_IN4'b0011 - MCASP3_AFSX_IN4'b0100 - MCASP4_AFSX_IN4'b0101 - MCASP0_AFSX_IN4'b0110 - MCASP1_AFSX_IN4'b0111 - MCASP2_AFSX_IN4'b1000 - MCASP3_AFSX_IN4'b1001 - MCASP4_AFSX_IN4'b1010 - AUDIO_EXT_REFCLK0_IN4'b1011 - AUDIO_EXT_REFCLK1_IN4'b1100 - AUDIO_EXT_REFCLK2_IN Reset Source: mod_g_rst_n
{0x82E0+4i} MAIN_CTRL_MMRCFG0_AUDIO_REFCLK{i}_CTRL reset 0xF (i=0..2) — Selects the clock source for the AUDIO_EXT_REFCLK0 output, and direction.
  [15] AUDIO_REFCLK{i}_CTRL_CLKOUT_EN — AUDIO_REFCLK {i} output enableField values (others are reserved):1'b0 - INPUT1'b1 - OUTPUT Reset Source: mod_g_rst_n
  [3:0] AUDIO_REFCLK{i}_CTRL_CLK_SEL — Selects the source of AUDIO_REFCLK{i}Field values (others are reserved):4'b0000 - MCASP0_AHCLKR4'b0001 - MCASP1_AHCLKR4'b0010 - MCASP2_AHCLKR4'b0011 - MCASP3_AHCLKR4'b0100 - MCASP4_AHCLKR4'b0101 - MCASP0_AHCLKX4'b0110 - MCASP1_AHCLKX4'b0111 - MCASP2_AHCLKX4'b1000 - MCASP3_AHCLKX4'b1001 - MCASP4_AHCLKX4'b1010 - ATCLK04'b1011 - ATCLK14'b1100 - ATCLK24'b1101 - ATCLK34'b1110 - MAIN_PLL1_HSDIV6_CLKOUTundefined - undefined4'b1111 - MAIN_PLL4_HSDIV0_CLKOUT Reset Source: mod_g_rst_n
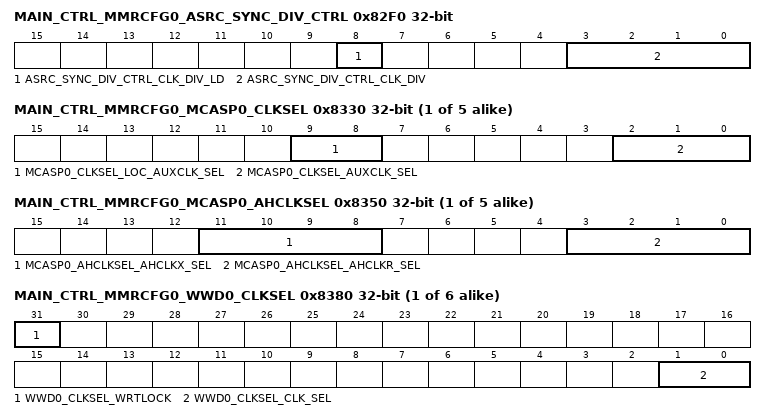
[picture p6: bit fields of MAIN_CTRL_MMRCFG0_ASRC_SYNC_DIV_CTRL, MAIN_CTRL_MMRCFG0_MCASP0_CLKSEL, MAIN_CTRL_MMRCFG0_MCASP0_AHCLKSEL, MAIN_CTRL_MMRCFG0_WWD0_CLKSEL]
0x82F0 MAIN_CTRL_MMRCFG0_ASRC_SYNC_DIV_CTRL — Selects additional divide value for the MAIN_PLL4 clock source to the ASRC RXSYNC and TXSYNC selection muxes
  [8] ASRC_SYNC_DIV_CTRL_CLK_DIV_LD — Load the divider valueWriting 1 to this bit will generate a load pulse to load the clk_div divider value. This bit can be cleared but must not be set in the same write cycle in which the clk_div value is changed. Field values (others are reserved):1'b0 - READY1'b1 - LOAD Reset Source: mod_g_rst_n
  [3:0] ASRC_SYNC_DIV_CTRL_CLK_DIV — ASRC Sync divider valueDivides MAIN_PLL4_HSDIV_CLKOUT3 by clkdiv+1. Supports divide by 1 to 16 (default to 1). To load the new divider value the clk_div_ld bit must be cleared and then set to 1. Reset Source: mod_g_rst_n
{0x8330+4i} MAIN_CTRL_MMRCFG0_MCASP{i}_CLKSEL (i=0..4) — Selects the functional clock source for McASP{i}
  [9:8] MCASP{i}_CLKSEL_LOC_AUXCLK_SEL — Selects the local clock source to use for McASP{i} AUXCLKField values (others are reserved):2'b00 - PLL4_REF_CLK (as selected by MAIN_PLL4_CLKSEL_clk_sel)2'b01 - PLL4_REF_CLK / 2 (as selected by MAIN_PLL4_CLKSEL_clk_sel)2'b10 - MAIN_PLL4_HSDIV0_CLKOUT Reset Source: mod_g_rst_n
  [2:0] MCASP{i}_CLKSEL_AUXCLK_SEL — Selects the system AUXCLK input source for McASP{i}Field values (others are reserved):3'b000 - MAIN_PLL2_HSDIV8_CLKOUT3'b001 - MAIN_PLL1_HSDIV6_CLKOUT3'b011 - AUDIO_EXT_REFCLK0 (Pin)3'b100 - AUDIO_EXT_REFCLK1 (Pin)3'b101 - AUDIO_EXT_REFCLK2 (Pin)3'b110 - ATCLK03'b111 - ATCLK1 Reset Source: mod_g_rst_n
{0x8350+4i} MAIN_CTRL_MMRCFG0_MCASP{i}_AHCLKSEL (i=0..4) — Selects the AHCLKX and AHCLKR clock source for McASP{i}
  [11:8] MCASP{i}_AHCLKSEL_AHCLKX_SEL — Selects the AHCLKX input source for McASP{i}Field values (others are reserved):4'b0000 - EXT_REFCLK1 (Pin)4'b0001 - HFOSC0_CLKOUT4'b0010 - AUDIO_EXT_REFCLK0 (Pin)4'b0011 - AUDIO_EXT_REFCLK1 (Pin)4'b0100 - AUDIO_EXT_REFCLK2 (Pin)undefined - undefined4'b0110 - MLB_IO_CLKundefined - undefined4'b1000 - ATCLK04'b1001 - ATCLK14'b1010 - ATCLK24'b1011 - ATCLK34'b1100 - CPSW CPTS GENF04'b1101 - CPSW CPTS GENF0 Reset Source: mod_g_rst_n
  [3:0] MCASP{i}_AHCLKSEL_AHCLKR_SEL — Selects the AHCLKR input source for McASP{i}Field values (others are reserved):4'b0000 - EXT_REFCLK1 (Pin)4'b0001 - HFOSC0_CLKOUT4'b0010 - AUDIO_EXT_REFCLK0 (Pin)4'b0011 - AUDIO_EXT_REFCLK1 (Pin)4'b0100 - AUDIO_EXT_REFCLK2 (Pin)undefined - undefined4'b0110 - MLB_IO_CLKundefined - undefined4'b1000 - ATCLK04'b1001 - ATCLK14'b1010 - ATCLK24'b1011 - ATCLK34'b1100 - CPSW CPTS GENF04'b1101 - CPSW CPTS GENF0 Reset Source: mod_g_rst_n
{0x8380+4i} MAIN_CTRL_MMRCFG0_WWD{i}_CLKSEL (i=0..5) — Windowed Watchdog WWD{i} functional clock selection control
  [31] WWD{i}_CLKSEL_WRTLOCK — When set, locks WWD{i}_CLKSEL from further writes until the next module reset.Field values (others are reserved):1'b0 - UNLOCKED1'b1 - LOCKED Reset Source: mod_g_rst_n
  [1:0] WWD{i}_CLKSEL_CLK_SEL — Windowed watchdog timer functional clock input select mux controlField values (others are reserved):2'b00 - HFOSC0_CLKOUT2'b01 - DEVICE_CLKOUT_32K2'b10 - CLK_12M_RC2'b11 - CLK_32K Reset Source: mod_g_rst_n
{0x83E0+4i} MAIN_CTRL_MMRCFG0_MCASP{i}_GF_CLK_SEL (i=0..4) — Performs glitchfree selection of the McASP{i} functional clock
  [16] MCASP{i}_GF_CLK_SEL_AUXCLK_GF_SEL — Provides glitch-free switching between the local and system AUXCLK source for McASP{i} based on MCASP{i}_CLKSEL loc_auxclk_sel and auxclk_sel settings.Field values (others are reserved):1'b0 - Use local AUXCLK source (as selected by loc_auxclk_sel bitfield)1'b1 - Use system AUXCLK source (as selected by auxsel_sel bitfield) Reset Source: mod_g_rst_n
{0x8480+4i} MAIN_CTRL_MMRCFG0_MCAN{i}_CLKSEL (i=0..4) — Controls the functional clock source for MCAN{i}
  [1:0] MCAN{i}_CLKSEL_CLK_SEL — MCAN functional clock selectionField values (others are reserved):2'b00 - MAIN_PLL0_HSDIV4_CLKOUT2'b01 - MCU_EXT_REFCLK0 (Pin)2'b10 - EXT_REFCLK1 (Pin)2'b11 - HFOSC0_CLKOUT Reset Source: sys_por_rst_n
{0x84C0+4i} MAIN_CTRL_MMRCFG0_ASRC0_RXSYNC{i}_SEL (i=0..3) — Selects the source signal for the ASRC0 RXSYNC{i} frame sync input
  [4:0] ASRC0_RXSYNC{i}_SEL_SYNC_SEL — RXSYNC source signalField values (others are reserved):5'b00000 - McASP0 AFSR Pin Input5'b00001 - McASP1 AFSR Pin Input5'b00010 - McASP2 AFSR Pin Input5'b00011 - McASP3 AFSR Pin Input5'b00100 - McASP4 AFSR Pin Input5'b00101 - '0' - Reserved5'b00110 - '0' - Reserved5'b00111 - '0' - Reserved5'b01000 - McASP0 AFSX Pin Input5'b01001 - McASP1 AFSX Pin Input5'b01010 - McASP2 AFSX Pin Input5'b01011 - McASP3 AFSX Pin Input5'b01100 - McASP4 AFSX Pin Input5'b01101 - '0' - Reserved5'b01110 - '0' - Reserved5'b01111 - '0' - Reserved5'b10000 - AUDIO_EXT_REFCLK0 Pin input5'b10001 - AUDIO_EXT_REFCLK1 Pin input5'b10010 - AUDIO_EXT_REFCLK2 Pin input5'b10011 - '0' - Reserved5'b10100 - ADC0_CLK5'b10101 - MLB_IO_CLK5'b10110 - MAIN_PLL4_HSDIV3_CLKOUT5'b10111 - '0' - Reserved5'b11000 - MCU_EXT_REFCLK0 Pin5'b11001 - EXT_REFCLK1 Pin5'b11010 - CPSW_CPTS_GENF05'b11011 - CPSW_CPTS_GENF15'b11100 - '0' - Reserved5'b11101 - '0' - Reserved5'b11110 - '0' - Reserved5'b11111 - '0' - Reserved Reset Source: mod_g_rst_n
{0x84D0+4i} MAIN_CTRL_MMRCFG0_ASRC1_RXSYNC{i}_SEL (i=0..3) — Selects the source signal for the ASRC1 RXSYNC{i} frame sync input
  [4:0] ASRC1_RXSYNC{i}_SEL_SYNC_SEL — RXSYNC source signalField values (others are reserved):5'b00000 - McASP0 AFSR Pin Input5'b00001 - McASP1 AFSR Pin Input5'b00010 - McASP2 AFSR Pin Input5'b00011 - McASP3 AFSR Pin Input5'b00100 - McASP4 AFSR Pin Input5'b00101 - '0' - Reserved5'b00110 - '0' - Reserved5'b00111 - '0' - Reserved5'b01000 - McASP0 AFSX Pin Input5'b01001 - McASP1 AFSX Pin Input5'b01010 - McASP2 AFSX Pin Input5'b01011 - McASP3 AFSX Pin Input5'b01100 - McASP4 AFSX Pin Input5'b01101 - '0' - Reserved5'b01110 - '0' - Reserved5'b01111 - '0' - Reserved5'b10000 - AUDIO_EXT_REFCLK0 Pin input5'b10001 - AUDIO_EXT_REFCLK1 Pin input5'b10010 - AUDIO_EXT_REFCLK2 Pin input5'b10011 - '0' - Reserved5'b10100 - ADC0_CLK5'b10101 - MLB_IO_CLK5'b10110 - MAIN_PLL4_HSDIV3_CLKOUT5'b10111 - '0' - Reserved5'b11000 - MCU_EXT_REFCLK0 Pin5'b11001 - EXT_REFCLK1 Pin5'b11010 - CPSW_CPTS_GENF05'b11011 - CPSW_CPTS_GENF15'b11100 - '0' - Reserved5'b11101 - '0' - Reserved5'b11110 - '0' - Reserved5'b11111 - '0' - Reserved Reset Source: mod_g_rst_n
{0x84E0+4i} MAIN_CTRL_MMRCFG0_ASRC0_TXSYNC{i}_SEL (i=0..3) — Selects the source signal for the ASRC0 TXSYNC{i} frame sync input
  [4:0] ASRC0_TXSYNC{i}_SEL_SYNC_SEL — TXSYNC source signalField values (others are reserved):5'b00000 - McASP0 AFSX Pin Input5'b00001 - McASP1 AFSX Pin Input5'b00010 - McASP2 AFSX Pin Input5'b00011 - McASP3 AFSX Pin Input5'b00100 - McASP4 AFSX Pin Input5'b00101 - '0' - Reserved5'b00110 - '0' - Reserved5'b00111 - '0' - Reserved5'b01000 - McASP0 AFSX Pin Input5'b01001 - McASP1 AFSX Pin Input5'b01010 - McASP2 AFSX Pin Input5'b01011 - McASP3 AFSX Pin Input5'b01100 - McASP4 AFSX Pin Input5'b01101 - '0' - Reserved5'b01110 - '0' - Reserved5'b01111 - '0' - Reserved5'b10000 - AUDIO_EXT_REFCLK0 Pin input5'b10001 - AUDIO_EXT_REFCLK1 Pin input5'b10010 - AUDIO_EXT_REFCLK2 Pin input5'b10011 - '0' - Reserved5'b10100 - ADC0_CLK5'b10101 - MLB_IO_CLK5'b10110 - MAIN_PLL4_HSDIV3_CLKOUT5'b10111 - '0' - Reserved5'b11000 - MCU_EXT_REFCLK0 Pin5'b11001 - EXT_REFCLK1 Pin5'b11010 - CPSW_CPTS_GENF05'b11011 - CPSW_CPTS_GENF15'b11100 - '0' - Reserved5'b11101 - '0' - Reserved5'b11110 - '0' - Reserved5'b11111 - '0' - Reserved Reset Source: mod_g_rst_n
